# AC7842x register map
Vendor: AutoChips; Series: AC78; File version: 1.0
CPU: CM4 r0p1, little endian, MPU, FPU, VTOR, 4 interrupt priority bits
Registers are 32-bit, read-write, reset 0x0 unless marked. A register's access mark holds for its fields unless they carry their own. Offsets are from the block's base; [hi:lo] are bit positions; {n}, {i} and the like mark numbered series.

## SENT_CHANNEL0
Base 0x40010100
Same registers: SENT_CHANNEL1 0x40010200
0x00 CPDR — Channel Pre Divider Regitser
  [11:0] PDIV — Channel frequency divided by (PDIV+1)
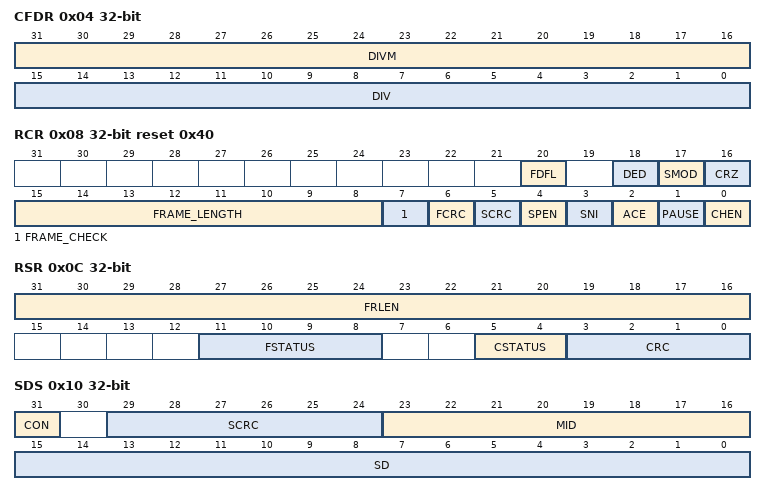
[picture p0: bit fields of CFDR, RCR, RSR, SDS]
0x04 CFDR — Channel Fractional Divider Regitser
  [31:16] DIVM ro — Measured divider value
  [15:0] DIV — Divider value
0x08 RCR reset 0x40 — Receive Data Control Register
  [20] FDFL — Frequency drift check based on frame length
    0=don't check; 1=check
  [18] DED — Drift error disable control
    0=Drift error enable; 1=Drift error disable
  [17] SMOD — Serial frame mode
    0=short serial format(16 frames,4 bit ID,8 bit data,4 bit CRC); 1=enhanced serial format(18 frames,4 or 8 bit ID,12 or 16 bit data,6 bit CRC)
  [16] CRZ — CRC augumentation with zero nibble control
    0=augumentation is selected for fast data nibbles and 4-bit CRC in serial data; 1=augumentation is switched off
  [15:8] FRAME_LENGTH — Determines the number of data nibbles per frame
  [7] FRAME_CHECK — Consecutive frame check direction
    0=Check against past sync pulse; 1=Check against future sync pulse
  [6] FCRC — Fast data CRC enable control
    0=Fast data CRC disable; 1=Fast data CRC enable
  [5] SCRC — Serial data CRC enable control
    0=Serial data CRC disable; 1=Serial data CRC enable
  [4] SPEN — Serial data processing enable control
    0=Serial data processing disable; 1=Serial data processing enable
  [3] SNI — Status nibble included in CRC control
    0=Status nibble not included in CRC; 1=Status nibble included in CRC
  [2] ACE — Alternate CRC mode enable control
    0=Alternate CRC mode disable; 1=Alternate CRC mode enable
  [1] PAUSE — Pause pulse enable control
    0=Pause pulse disable; 1=Pause pulse enable
  [0] CHEN — Channel enable control
    0=Chandnel disable; 1=Chandnel enable
0x0C RSR — Receive Data Status Register
  [31:16] FRLEN ro — Frame length including pause nibble
  [11:8] FSTATUS ro — Fast data status nibble
  [5:4] CSTATUS ro — Channel status
    0=STOP, channel is disabled; 1=INITIALZIED, channel is enabled and configured; 2=RUNNING, receive 1 or more sync pulse that frequency range is invalid, fallback status from SYNCHRONIZED; 3=SYNCHRONIZED, frequency range is valid.This status can be jumped from INITIALZIED and RUNNING
  [3:0] CRC ro — Fast data CRC value
0x10 SDS — Serial Data and Status Register
  [31] CON ro — Configuration bit
  [29:24] SCRC ro — Serial message CRC
  [23:16] MID ro — Serial message ID
  [15:0] SD ro — Serial data
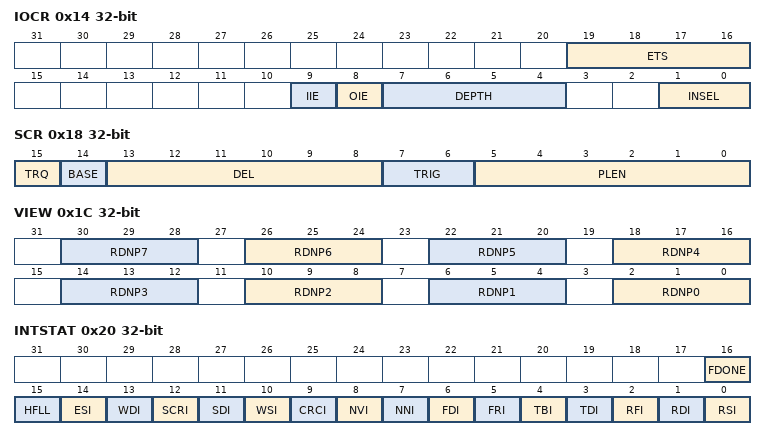
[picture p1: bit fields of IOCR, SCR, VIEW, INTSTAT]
0x14 IOCR — Input and Output Control Register
  [19:16] ETS — External trigger select
    {v}=TRIG{v} (v=0..3)
  [9] IIE — Input inverter enable control
    0=Input inverter disable, pulse polarity is active low; 1=Input inverter enable, pulse polarity is active high
  [8] OIE — Output inverter enable control
    0=Output inverter disable, pulse polarity is active low; 1=Output inverter enable, pulse polarity is active high
  [7:4] DEPTH — Digital glitch filter depth
  [1:0] INSEL — Input select
    0=choose input 0; 1=choose input 1
0x18 SCR — SPC Control Register
  [15] TRQ — Transfer request in progress
    0=SPC pulse is not being sent; 1=SPC pulse is being sent
  [14] BASE — Time base
    0=Pulse is based on measured frequency of last sync pulse; 1=Pulse is based on nominal frequency
  [13:8] DEL — Selects how long the SPC pulse is delayed after the trigger condition
  [7:6] TRIG — Trigger source and mode selection
    0=No pulse is generated; 1=Pulse starts immediately(no auto repetition); 2=Pulse starts each time the first falling edge of any sync pulse, auto repeated on next sync pulse; 3=Pulse starts after each external trigger event
  [5:0] PLEN — Pulse length
0x1C VIEW — Receive Data View Register
  [4n+2:4n] RDNP{n} (n=0..7) — Receive data target nibble pointer {n}
0x20 INTSTAT — Interrupt Status Register
  [16] FDONE ro — Current frame receive done request flag
  [15] HFLL ro — FIFO half full interrupt request flag
  [14] ESI ro — Enhanced serial message start bit error request flag
  [13] WDI ro — Watchdog error request flag
  [12] SCRI ro — Serial data CRC error request flag
  [11] SDI ro — Serial data receive interrupt request flag
  [10] WSI ro — Wrong status and communication nibble error request flag
  [9] CRCI ro — CRC error request flag
  [8] NVI ro — Nibbles value out of range request flag
  [7] NNI ro — Number of nibbles wrong interrupt request flag
  [6] FDI ro — Frequency drift interrupt request flag
  [5] FRI ro — Frequency out of range interrupt request flag
  [4] TBI ro — Transfer buffer underflow interrupt request flag
  [3] TDI ro — Transfer data interrupt request flag
  [2] RFI ro — Receive FIFO overflow interrupt request flag
  [1] RDI ro — Receive success interrupt request flag
  [0] RSI ro — Receive success interrupt request flag
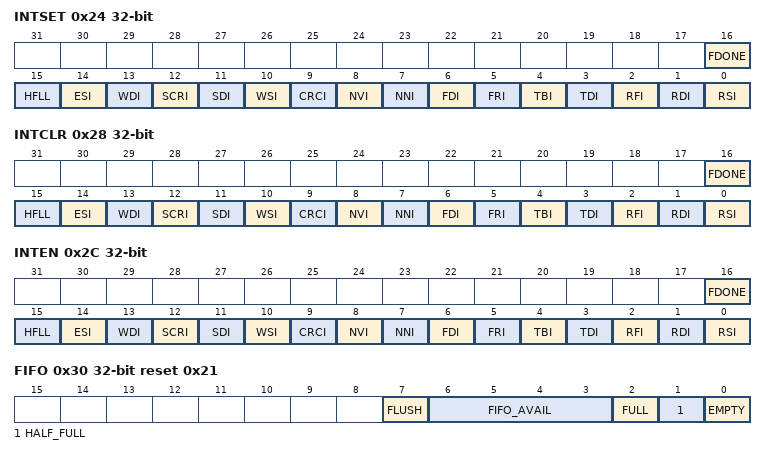
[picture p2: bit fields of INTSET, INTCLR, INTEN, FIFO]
0x24 INTSET — Interrupt Set Register
  [16] FDONE — Set interrupt request flag FDONE
  [15] HFLL — Set interrupt request flag HFLL
  [14] ESI — Set interrupt request flag ESI
  [13] WDI — Set interrupt request flag WDI
  [12] SCRI — Set interrupt request flag SCRI
  [11] SDI — Set interrupt request flag SDI
  [10] WSI — Set interrupt request flag WSI
  [9] CRCI — Set interrupt request flag CRCI
  [8] NVI — Set interrupt request flag NVI
  [7] NNI — Set interrupt request flag NNI
  [6] FDI — Set interrupt request flag FDI
  [5] FRI — Set interrupt request flag FRI
  [4] TBI — Set interrupt request flag TBI
  [3] TDI — Set interrupt request flag TDI
  [2] RFI — Set interrupt request flag RFI
  [1] RDI — Set interrupt request flag RDI
  [0] RSI — Set interrupt request flag RSI
0x28 INTCLR — Interrupt Clear Register
  [16] FDONE — Clear interrupt request flag FDONE
  [15] HFLL — Clear interrupt request flag HFLL
  [14] ESI — Clear interrupt request flag ESI
  [13] WDI — Clear interrupt request flag WDI
  [12] SCRI — Clear interrupt request flag SCRI
  [11] SDI — Clear interrupt request flag SDI
  [10] WSI — Clear interrupt request flag WSI
  [9] CRCI — Clear interrupt request flag CRCI
  [8] NVI — Clear interrupt request flag NVI
  [7] NNI — Clear interrupt request flag NNI
  [6] FDI — Clear interrupt request flag FDI
  [5] FRI — Clear interrupt request flag FRI
  [4] TBI — Clear interrupt request flag TBI
  [3] TDI — Clear interrupt request flag TDI
  [2] RFI — Clear interrupt request flag RFI
  [1] RDI — Clear interrupt request flag RDI
  [0] RSI — Clear interrupt request flag RSI
0x2C INTEN — Interrupt Enable Register
  [16] FDONE — Enable interrupt request flag FDONE
  [15] HFLL — Enable interrupt request flag HFLL
  [14] ESI — Enable interrupt request flag ESI
  [13] WDI — Enable interrupt request flag WDI
  [12] SCRI — Enable interrupt request flag SCRI
  [11] SDI — Enable interrupt request flag SDI
  [10] WSI — Enable interrupt request flag WSI
  [9] CRCI — Enable interrupt request flag CRCI
  [8] NVI — Enable interrupt request flag NVI
  [7] NNI — Enable interrupt request flag NNI
  [6] FDI — Enable interrupt request flag FDI
  [5] FRI — Enable interrupt request flag FRI
  [4] TBI — Enable interrupt request flag TBI
  [3] TDI — Enable interrupt request flag TDI
  [2] RFI — Enable interrupt request flag RFI
  [1] RDI — Enable interrupt request flag RDI
  [0] RSI — Enable interrupt request flag RSI
0x30 FIFO reset 0x21 — FIFO Control Register
  [7] FLUSH — FIFO flush
    0=Fifo normal work; 1=Fifo is flushed, write and read pointer cleared
  [6:3] FIFO_AVAIL ro — FIFO Avail data space
  [2] FULL ro — FIFO full flag
  [1] HALF_FULL ro — FIFO half full flag
  [0] EMPTY ro — FIFO empty flag
0x34 WDT — Watch Dog Timer Register
  [15:0] WDL — Watchdog Timer Limit
0x38 RDR — Receive Data Register
  [31:0] RDR — Receive data nibbles
